# WKUP_CTRL_MMR0_CFG0 register map
Vendor: Texas Instruments
Registers are 32-bit, read-write, reset 0x0 unless marked. A register's access mark holds for its fields unless they carry their own. Offsets are as the file gives them; [hi:lo] are bit positions; {n}, {i} and the like mark numbered series.

## WKUP_CTRL_MMR0_CFG0 (part 5 of 11)
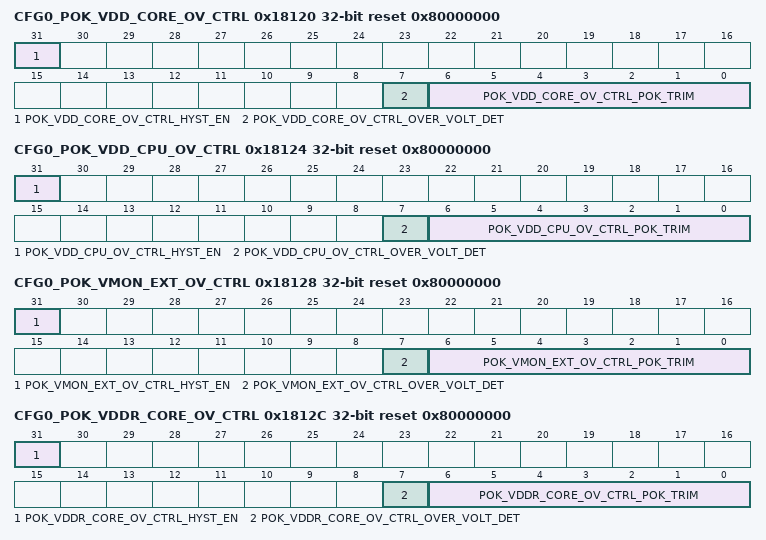
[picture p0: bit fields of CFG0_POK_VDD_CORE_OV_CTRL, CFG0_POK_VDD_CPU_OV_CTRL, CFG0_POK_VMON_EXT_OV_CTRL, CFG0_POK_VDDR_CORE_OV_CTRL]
0x18120 CFG0_POK_VDD_CORE_OV_CTRL reset 0x80000000
  [31] POK_VDD_CORE_OV_CTRL_HYST_EN — Enable POK hysteresis
  [7] POK_VDD_CORE_OV_CTRL_OVER_VOLT_DET — Over / under voltage detection mode 0 - Under voltage detection 1 - Over voltage detection
  [6:0] POK_VDD_CORE_OV_CTRL_POK_TRIM — POK trim bits. These bits are used to trim the comparator threshold voltage. See POK spec and efuse spec for details
0x18124 CFG0_POK_VDD_CPU_OV_CTRL reset 0x80000000
  [31] POK_VDD_CPU_OV_CTRL_HYST_EN — Enable POK hysteresis
  [7] POK_VDD_CPU_OV_CTRL_OVER_VOLT_DET — Over / under voltage detection mode 0 - Under voltage detection 1 - Over voltage detection
  [6:0] POK_VDD_CPU_OV_CTRL_POK_TRIM — POK trim bits. These bits are used to trim the comparator threshold voltage. See POK spec and efuse spec for details
0x18128 CFG0_POK_VMON_EXT_OV_CTRL reset 0x80000000
  [31] POK_VMON_EXT_OV_CTRL_HYST_EN — Enable POK hysteresis
  [7] POK_VMON_EXT_OV_CTRL_OVER_VOLT_DET — Over / under voltage detection mode 0 - Under voltage detection 1 - Over voltage detection
  [6:0] POK_VMON_EXT_OV_CTRL_POK_TRIM — POK trim bits. These bits are used to trim the comparator threshold voltage. See POK spec and efuse spec for details
0x1812C CFG0_POK_VDDR_CORE_OV_CTRL reset 0x80000000
  [31] POK_VDDR_CORE_OV_CTRL_HYST_EN — Enable POK hysteresis
  [7] POK_VDDR_CORE_OV_CTRL_OVER_VOLT_DET — Over / under voltage detection mode 0 - Under voltage detection 1 - Over voltage detection
  [6:0] POK_VDDR_CORE_OV_CTRL_POK_TRIM — POK trim bits. These bits are used to trim the comparator threshold voltage. See POK spec and efuse spec for details
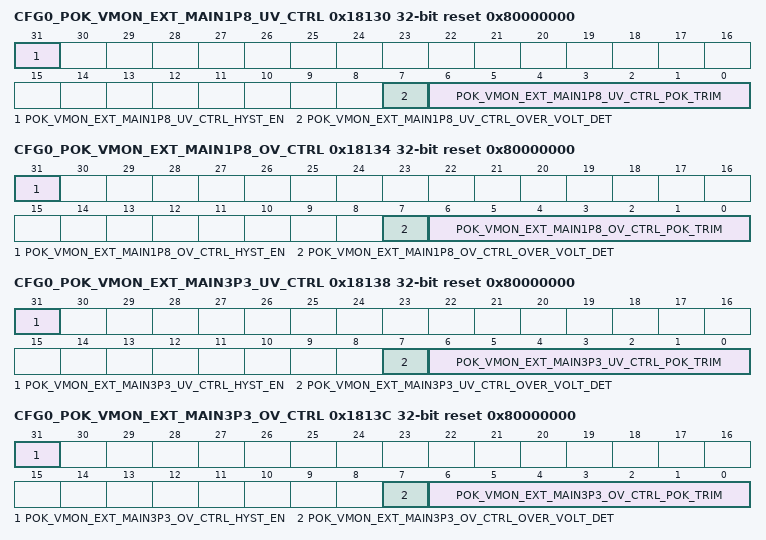
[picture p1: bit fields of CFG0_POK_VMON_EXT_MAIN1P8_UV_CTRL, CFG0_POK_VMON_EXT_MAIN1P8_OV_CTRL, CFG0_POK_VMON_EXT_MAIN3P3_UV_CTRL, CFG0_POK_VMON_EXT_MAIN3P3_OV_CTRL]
0x18130 CFG0_POK_VMON_EXT_MAIN1P8_UV_CTRL reset 0x80000000
  [31] POK_VMON_EXT_MAIN1P8_UV_CTRL_HYST_EN — Enable POK hysteresis
  [7] POK_VMON_EXT_MAIN1P8_UV_CTRL_OVER_VOLT_DET — Over / under voltage detection mode 0 - Under voltage detection 1 - Over voltage detection
  [6:0] POK_VMON_EXT_MAIN1P8_UV_CTRL_POK_TRIM — POK trim bits. These bits are used to trim the comparator threshold voltage. See POK spec and efuse spec for details
0x18134 CFG0_POK_VMON_EXT_MAIN1P8_OV_CTRL reset 0x80000000
  [31] POK_VMON_EXT_MAIN1P8_OV_CTRL_HYST_EN — Enable POK hysteresis
  [7] POK_VMON_EXT_MAIN1P8_OV_CTRL_OVER_VOLT_DET — Over / under voltage detection mode 0 - Under voltage detection 1 - Over voltage detection
  [6:0] POK_VMON_EXT_MAIN1P8_OV_CTRL_POK_TRIM — POK trim bits. These bits are used to trim the comparator threshold voltage. See POK spec and efuse spec for details
0x18138 CFG0_POK_VMON_EXT_MAIN3P3_UV_CTRL reset 0x80000000
  [31] POK_VMON_EXT_MAIN3P3_UV_CTRL_HYST_EN — Enable POK hysteresis
  [7] POK_VMON_EXT_MAIN3P3_UV_CTRL_OVER_VOLT_DET — Over / under voltage detection mode 0 - Under voltage detection 1 - Over voltage detection
  [6:0] POK_VMON_EXT_MAIN3P3_UV_CTRL_POK_TRIM — POK trim bits. These bits are used to trim the comparator threshold voltage. See POK spec and efuse spec for details
0x1813C CFG0_POK_VMON_EXT_MAIN3P3_OV_CTRL reset 0x80000000
  [31] POK_VMON_EXT_MAIN3P3_OV_CTRL_HYST_EN — Enable POK hysteresis
  [7] POK_VMON_EXT_MAIN3P3_OV_CTRL_OVER_VOLT_DET — Over / under voltage detection mode 0 - Under voltage detection 1 - Over voltage detection
  [6:0] POK_VMON_EXT_MAIN3P3_OV_CTRL_POK_TRIM — POK trim bits. These bits are used to trim the comparator threshold voltage. See POK spec and efuse spec for details
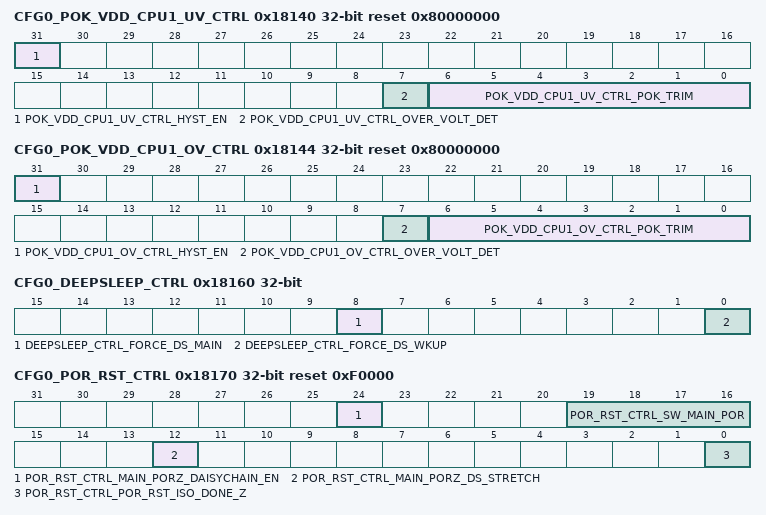
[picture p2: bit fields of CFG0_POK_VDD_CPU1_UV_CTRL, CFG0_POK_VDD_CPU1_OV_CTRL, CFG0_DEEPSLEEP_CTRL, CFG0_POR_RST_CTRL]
0x18140 CFG0_POK_VDD_CPU1_UV_CTRL reset 0x80000000
  [31] POK_VDD_CPU1_UV_CTRL_HYST_EN — Enable POK hysteresis
  [7] POK_VDD_CPU1_UV_CTRL_OVER_VOLT_DET — Over / under voltage detection mode 0 - Under voltage detection 1 - Over voltage detection
  [6:0] POK_VDD_CPU1_UV_CTRL_POK_TRIM — POK trim bits. These bits are used to trim the comparator threshold voltage. See POK spec and efuse spec for details
0x18144 CFG0_POK_VDD_CPU1_OV_CTRL reset 0x80000000
  [31] POK_VDD_CPU1_OV_CTRL_HYST_EN — Enable POK hysteresis
  [7] POK_VDD_CPU1_OV_CTRL_OVER_VOLT_DET — Over / under voltage detection mode 0 - Under voltage detection 1 - Over voltage detection
  [6:0] POK_VDD_CPU1_OV_CTRL_POK_TRIM — POK trim bits. These bits are used to trim the comparator threshold voltage. See POK spec and efuse spec for details
{0x18150+4i} CFG0_POK_RSV{i} access not given (i=0..3)
0x18160 CFG0_DEEPSLEEP_CTRL
  [8] DEEPSLEEP_CTRL_FORCE_DS_MAIN — Force all MAIN IOs into deepsleep mode when set
  [0] DEEPSLEEP_CTRL_FORCE_DS_WKUP — Force all WKUP IOs into deepsleep mode when set
0x18170 CFG0_POR_RST_CTRL reset 0xF0000
  [24] POR_RST_CTRL_MAIN_PORZ_DAISYCHAIN_EN — MAIN PORz daisy-chain event enable. Determines if MAIN PORz reset events affect daisy-chain wakeup 0 - DeepSleep MAIN PORz event is not part of daisy-chain 1 - DeepSleep MAIN PORz event is combined w/ other daisy chain events.
  [19:16] POR_RST_CTRL_SW_MAIN_POR — Main Domain software power-on reset. When set to 4'b0110, a power-on is issued to the MAIN voltage domain. (Bits will reset to 4'b1111 on reset of the Main Domain)
  [12] POR_RST_CTRL_MAIN_PORZ_DS_STRETCH — DeepSleep mode MAIN PORz stretch. 0 - No stretching 1 - Stretch the Main PORz event captured during DeepSleep mode
  [0] POR_RST_CTRL_POR_RST_ISO_DONE_Z — Reset isolation completion (active low). This bit should be cleared only after reset isolation of the MAIN domain is complete. 0 - POR reset propagates to MAIN domain 1 - POR reset blocked from MAIN domain
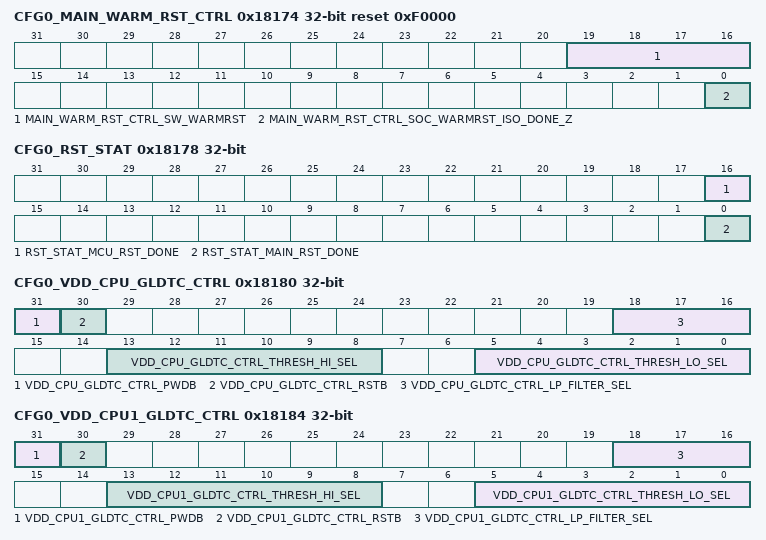
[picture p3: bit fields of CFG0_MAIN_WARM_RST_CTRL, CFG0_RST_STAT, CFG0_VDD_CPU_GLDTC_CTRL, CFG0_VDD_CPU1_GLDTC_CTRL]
0x18174 CFG0_MAIN_WARM_RST_CTRL reset 0xF0000
  [19:16] MAIN_WARM_RST_CTRL_SW_WARMRST — Main Domain software warm reset. When set to 4'b0110, a warm reset is issued to the MAIN voltage domain. (Bits will reset to 4'b1111 on reset of the Main Domain)
  [0] MAIN_WARM_RST_CTRL_SOC_WARMRST_ISO_DONE_Z — Reset isolation completion (active low). This bit should be cleared only after reset isolation of the MAIN domain is complete. 0 - Warm reset propagates to MAIN domain 1 - Warm reset blocked from MAIN domain
0x18178 CFG0_RST_STAT ro
  [16] RST_STAT_MCU_RST_DONE — Indicates MCU domain reset status. 0 - MCU domain is in reset 1 - MCU domain reset is complete
  [0] RST_STAT_MAIN_RST_DONE — Indicates MAIN domain Warm reset status. 0 - MAIN domain is in Warm reset 1 - MAIN domain Warm reset is complete
0x1817C CFG0_MCU_WARM_RST_CTRL reset 0xF0000
  [19:16] MCU_WARM_RST_CTRL_SW_WARMRST — Chip software warm reset. When set to 4'b0110, a warm reset is issued to the device (all voltage domains). (Bits will reset to 4'b1111 on reset completion.)
0x18180 CFG0_VDD_CPU_GLDTC_CTRL
  [31] VDD_CPU_GLDTC_CTRL_PWDB — Power down - active low. 0 - Disable all functions 1 - Enable glitch detectors
  [30] VDD_CPU_GLDTC_CTRL_RSTB — Reset - active low. To ensure proper operation, rstb must be not be de-asserted for at least 100 ns after power-up (pwdb de-asserted). Additionally, rstb must be toggled low at least 200 ns after any change in threshold or low-pass filter settings to prevent abnormal trigger events. 0 - Reset glitch detector flags 1 - Glitch detection flags are enabled
  [18:16] VDD_CPU_GLDTC_CTRL_LP_FILTER_SEL — Selects the glitch detect low-pass filter bandwidth Field values (others are reserved): 3'b000 - 150 kHz 3'b001 - 125 kHz 3'b010 - 100 kHz 3'b011 - 80 kHz 3'b100 - 60 kHz 3'b101 - 45 kHz 3'b110 - 30 kHz 3'b111 - 15 kHz
  [13:8] VDD_CPU_GLDTC_CTRL_THRESH_HI_SEL — Selects the high voltage glitch threshold as a percentage of the monitored voltage Field values (others are reserved): 6'b000000 - 93.5% of VDD 6'b000001 - 94.0% of VDD 6'b000010 - 94.5% of VDD 6'b000011 - 95.0% of VDD 6'b000100 - 95.5% of VDD 6'b000101 - 96.0% of VDD 6'b000110 - 96.5% of VDD 6'b000111 - 97.0% of VDD 6'b001000 - 97.5% of VDD 6'b001001 - 98.0% of VDD 6'b001010 - 98.5% of VDD 6'b001011 - 99.0% of VDD 6'b001100 - 99.5% of VDD 6'b001101 - 100.0% of VDD 6'b001110 - 100.5% of VDD 6'b001111 - 101.0% of VDD 6'b010000 - 101.5% of VDD 6'b010001 - 102.0% of VDD 6'b010010 - 102.5% of VDD 6'b010011 - 103.0% of VDD 6'b010100 - 103.5% of VDD 6'b010101 - 104.0% of VDD 6'b010110 - 104.5% of VDD 6'b010111 - 105.0% of VDD 6'b011000 - 105.5% of VDD 6'b011001 - 106.0% of VDD 6'b011010 - 106.5% of VDD 6'b011011 - 107.0% of VDD 6'b011100 - 107.5% of VDD 6'b011101 - 108.0% of VDD 6'b011110 - 108.5% of VDD 6'b011111 - 109.0% of VDD 6'b100000 - 109.5% of VDD 6'b100001 - 110.0% of VDD 6'b100010 - 111.0% of VDD 6'b100011 - 112.0% of VDD 6'b100100 - 113.0% of VDD 6'b100101 - 114.0% of VDD 6'b100110 - 115.0% of VDD 6'b100111 - 116.0% of VDD 6'b101000 - 117.0% of VDD 6'b101001 - 118.0% of VDD 6'b101010 - 119.0% of VDD 6'b101011 - 120.0% of VDD 6'b101100 - 121.0% of VDD 6'b101101 - 122.0% of VDD 6'b101110 - 123.0% of VDD 6'b101111 - 124.0% of VDD 6'b110000 - 125.0% of VDD 6'b110001 - 126.0% of VDD 6'b110010 - 127.0% of VDD 6'b110011 - 128.0% of VDD 6'b110100 - 129.0% of VDD 6'b110101 - 130.0% of VDD 6'b110110 - 131.0% of VDD 6'b110111 - 132.0% of VDD 6'b111000 - 133.0% of VDD 6'b111001 - 134.0% of VDD 6'b111010 - 135.0% of VDD 6'b111011 - 136.0% of VDD 6'b111100 - 137.0% of VDD 6'b111101 - 138.0% of VDD 6'b111110 - 139.0% of VDD 6'b111111 - 140.0% of VDD
  [5:0] VDD_CPU_GLDTC_CTRL_THRESH_LO_SEL — Selects the low voltage glitch threshold as a percentage of the monitored voltage Field values (others are reserved): 6'b000000 - 106.5% of VDD 6'b000001 - 106.0% of VDD 6'b000010 - 105.5% of VDD 6'b000011 - 105.0% of VDD 6'b000100 - 104.5% of VDD 6'b000101 - 104.0% of VDD 6'b000110 - 103.5% of VDD 6'b000111 - 103.0% of VDD 6'b001000 - 102.5% of VDD 6'b001001 - 102.0% of VDD 6'b001010 - 101.5% of VDD 6'b001011 - 101.0% of VDD 6'b001100 - 100.5% of VDD 6'b001101 - 100.0% of VDD 6'b001110 - 99.5% of VDD 6'b001111 - 99.0% of VDD 6'b010000 - 98.5% of VDD 6'b010001 - 98.0% of VDD 6'b010010 - 97.5% of VDD 6'b010011 - 97.0% of VDD 6'b010100 - 96.5% of VDD 6'b010101 - 96.0% of VDD 6'b010110 - 95.5% of VDD 6'b010111 - 95.0% of VDD 6'b011000 - 94.5% of VDD 6'b011001 - 94.0% of VDD 6'b011010 - 93.5% of VDD 6'b011011 - 93.0% of VDD 6'b011100 - 92.5% of VDD 6'b011101 - 92.0% of VDD 6'b011110 - 91.5% of VDD 6'b011111 - 91.0% of VDD 6'b100000 - 90.5% of VDD 6'b100001 - 90.0% of VDD 6'b100010 - 89.0% of VDD 6'b100011 - 88.0% of VDD 6'b100100 - 87.0% of VDD 6'b100101 - 86.0% of VDD 6'b100110 - 85.0% of VDD 6'b100111 - 84.0% of VDD 6'b101000 - 83.0% of VDD 6'b101001 - 82.0% of VDD 6'b101010 - 81.0% of VDD 6'b101011 - 80.0% of VDD 6'b101100 - 79.0% of VDD 6'b101101 - 78.0% of VDD 6'b101110 - 77.0% of VDD 6'b101111 - 76.0% of VDD 6'b110000 - 75.0% of VDD 6'b110001 - 74.0% of VDD 6'b110010 - 73.0% of VDD 6'b110011 - 72.0% of VDD 6'b110100 - 71.0% of VDD 6'b110101 - 70.0% of VDD 6'b110110 - 69.0% of VDD 6'b110111 - 68.0% of VDD 6'b111000 - 67.0% of VDD 6'b111001 - 66.0% of VDD 6'b111010 - 65.0% of VDD 6'b111011 - 64.0% of VDD 6'b111100 - 63.0% of VDD 6'b111101 - 62.0% of VDD 6'b111110 - 61.0% of VDD 6'b111111 - 60.0% of VDD
0x18184 CFG0_VDD_CPU1_GLDTC_CTRL
  [31] VDD_CPU1_GLDTC_CTRL_PWDB — Power down - active low. 0 - Disable all functions 1 - Enable glitch detectors
  [30] VDD_CPU1_GLDTC_CTRL_RSTB — Reset - active low. To ensure proper operation, rstb must be not be de-asserted for at least 100 ns after power-up (pwdb de-asserted). Additionally, rstb must be toggled low at least 200 ns after any change in threshold or low-pass filter settings to prevent abnormal trigger events. 0 - Reset glitch detector flags 1 - Glitch detection flags are enabled
  [18:16] VDD_CPU1_GLDTC_CTRL_LP_FILTER_SEL — Selects the glitch detect low-pass filter bandwidth Field values (others are reserved): 3'b000 - 150 kHz 3'b001 - 125 kHz 3'b010 - 100 kHz 3'b011 - 80 kHz 3'b100 - 60 kHz 3'b101 - 45 kHz 3'b110 - 30 kHz 3'b111 - 15 kHz
  [13:8] VDD_CPU1_GLDTC_CTRL_THRESH_HI_SEL — Selects the high voltage glitch threshold as a percentage of the monitored voltage Field values (others are reserved): 6'b000000 - 93.5% of VDD 6'b000001 - 94.0% of VDD 6'b000010 - 94.5% of VDD 6'b000011 - 95.0% of VDD 6'b000100 - 95.5% of VDD 6'b000101 - 96.0% of VDD 6'b000110 - 96.5% of VDD 6'b000111 - 97.0% of VDD 6'b001000 - 97.5% of VDD 6'b001001 - 98.0% of VDD 6'b001010 - 98.5% of VDD 6'b001011 - 99.0% of VDD 6'b001100 - 99.5% of VDD 6'b001101 - 100.0% of VDD 6'b001110 - 100.5% of VDD 6'b001111 - 101.0% of VDD 6'b010000 - 101.5% of VDD 6'b010001 - 102.0% of VDD 6'b010010 - 102.5% of VDD 6'b010011 - 103.0% of VDD 6'b010100 - 103.5% of VDD 6'b010101 - 104.0% of VDD 6'b010110 - 104.5% of VDD 6'b010111 - 105.0% of VDD 6'b011000 - 105.5% of VDD 6'b011001 - 106.0% of VDD 6'b011010 - 106.5% of VDD 6'b011011 - 107.0% of VDD 6'b011100 - 107.5% of VDD 6'b011101 - 108.0% of VDD 6'b011110 - 108.5% of VDD 6'b011111 - 109.0% of VDD 6'b100000 - 109.5% of VDD 6'b100001 - 110.0% of VDD 6'b100010 - 111.0% of VDD 6'b100011 - 112.0% of VDD 6'b100100 - 113.0% of VDD 6'b100101 - 114.0% of VDD 6'b100110 - 115.0% of VDD 6'b100111 - 116.0% of VDD 6'b101000 - 117.0% of VDD 6'b101001 - 118.0% of VDD 6'b101010 - 119.0% of VDD 6'b101011 - 120.0% of VDD 6'b101100 - 121.0% of VDD 6'b101101 - 122.0% of VDD 6'b101110 - 123.0% of VDD 6'b101111 - 124.0% of VDD 6'b110000 - 125.0% of VDD 6'b110001 - 126.0% of VDD 6'b110010 - 127.0% of VDD 6'b110011 - 128.0% of VDD 6'b110100 - 129.0% of VDD 6'b110101 - 130.0% of VDD 6'b110110 - 131.0% of VDD 6'b110111 - 132.0% of VDD 6'b111000 - 133.0% of VDD 6'b111001 - 134.0% of VDD 6'b111010 - 135.0% of VDD 6'b111011 - 136.0% of VDD 6'b111100 - 137.0% of VDD 6'b111101 - 138.0% of VDD 6'b111110 - 139.0% of VDD 6'b111111 - 140.0% of VDD
  [5:0] VDD_CPU1_GLDTC_CTRL_THRESH_LO_SEL — Selects the low voltage glitch threshold as a percentage of the monitored voltage Field values (others are reserved): 6'b000000 - 106.5% of VDD 6'b000001 - 106.0% of VDD 6'b000010 - 105.5% of VDD 6'b000011 - 105.0% of VDD 6'b000100 - 104.5% of VDD 6'b000101 - 104.0% of VDD 6'b000110 - 103.5% of VDD 6'b000111 - 103.0% of VDD 6'b001000 - 102.5% of VDD 6'b001001 - 102.0% of VDD 6'b001010 - 101.5% of VDD 6'b001011 - 101.0% of VDD 6'b001100 - 100.5% of VDD 6'b001101 - 100.0% of VDD 6'b001110 - 99.5% of VDD 6'b001111 - 99.0% of VDD 6'b010000 - 98.5% of VDD 6'b010001 - 98.0% of VDD 6'b010010 - 97.5% of VDD 6'b010011 - 97.0% of VDD 6'b010100 - 96.5% of VDD 6'b010101 - 96.0% of VDD 6'b010110 - 95.5% of VDD 6'b010111 - 95.0% of VDD 6'b011000 - 94.5% of VDD 6'b011001 - 94.0% of VDD 6'b011010 - 93.5% of VDD 6'b011011 - 93.0% of VDD 6'b011100 - 92.5% of VDD 6'b011101 - 92.0% of VDD 6'b011110 - 91.5% of VDD 6'b011111 - 91.0% of VDD 6'b100000 - 90.5% of VDD 6'b100001 - 90.0% of VDD 6'b100010 - 89.0% of VDD 6'b100011 - 88.0% of VDD 6'b100100 - 87.0% of VDD 6'b100101 - 86.0% of VDD 6'b100110 - 85.0% of VDD 6'b100111 - 84.0% of VDD 6'b101000 - 83.0% of VDD 6'b101001 - 82.0% of VDD 6'b101010 - 81.0% of VDD 6'b101011 - 80.0% of VDD 6'b101100 - 79.0% of VDD 6'b101101 - 78.0% of VDD 6'b101110 - 77.0% of VDD 6'b101111 - 76.0% of VDD 6'b110000 - 75.0% of VDD 6'b110001 - 74.0% of VDD 6'b110010 - 73.0% of VDD 6'b110011 - 72.0% of VDD 6'b110100 - 71.0% of VDD 6'b110101 - 70.0% of VDD 6'b110110 - 69.0% of VDD 6'b110111 - 68.0% of VDD 6'b111000 - 67.0% of VDD 6'b111001 - 66.0% of VDD 6'b111010 - 65.0% of VDD 6'b111011 - 64.0% of VDD 6'b111100 - 63.0% of VDD 6'b111101 - 62.0% of VDD 6'b111110 - 61.0% of VDD 6'b111111 - 60.0% of VDD
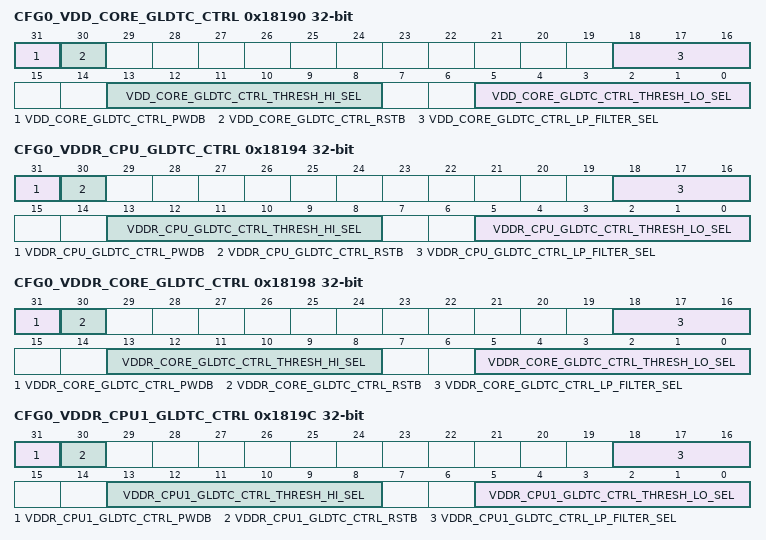
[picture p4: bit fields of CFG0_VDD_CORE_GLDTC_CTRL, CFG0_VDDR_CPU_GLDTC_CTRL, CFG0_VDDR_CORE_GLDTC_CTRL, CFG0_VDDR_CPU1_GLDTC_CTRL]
0x18190 CFG0_VDD_CORE_GLDTC_CTRL
  [31] VDD_CORE_GLDTC_CTRL_PWDB — Power down - active low. 0 - Disable all functions 1 - Enable glitch detectors
  [30] VDD_CORE_GLDTC_CTRL_RSTB — Reset - active low. To ensure proper operation, rstb must be not be de-asserted for at least 100 ns after power-up (pwdb de-asserted). Additionally, rstb must be toggled low at least 200 ns after any change in threshold or low-pass filter settings to prevent abnormal trigger events. 0 - Reset glitch detector flags 1 - Glitch detection flags are enabled
  [18:16] VDD_CORE_GLDTC_CTRL_LP_FILTER_SEL — Selects the glitch detect low-pass filter bandwidth Field values (others are reserved): 3'b000 - 150 kHz 3'b001 - 125 kHz 3'b010 - 100 kHz 3'b011 - 80 kHz 3'b100 - 60 kHz 3'b101 - 45 kHz 3'b110 - 30 kHz 3'b111 - 15 kHz
  [13:8] VDD_CORE_GLDTC_CTRL_THRESH_HI_SEL — Selects the high voltage glitch threshold as a percentage of the monitored voltage Field values (others are reserved): 6'b000000 - 93.5% of VDD 6'b000001 - 94.0% of VDD 6'b000010 - 94.5% of VDD 6'b000011 - 95.0% of VDD 6'b000100 - 95.5% of VDD 6'b000101 - 96.0% of VDD 6'b000110 - 96.5% of VDD 6'b000111 - 97.0% of VDD 6'b001000 - 97.5% of VDD 6'b001001 - 98.0% of VDD 6'b001010 - 98.5% of VDD 6'b001011 - 99.0% of VDD 6'b001100 - 99.5% of VDD 6'b001101 - 100.0% of VDD 6'b001110 - 100.5% of VDD 6'b001111 - 101.0% of VDD 6'b010000 - 101.5% of VDD 6'b010001 - 102.0% of VDD 6'b010010 - 102.5% of VDD 6'b010011 - 103.0% of VDD 6'b010100 - 103.5% of VDD 6'b010101 - 104.0% of VDD 6'b010110 - 104.5% of VDD 6'b010111 - 105.0% of VDD 6'b011000 - 105.5% of VDD 6'b011001 - 106.0% of VDD 6'b011010 - 106.5% of VDD 6'b011011 - 107.0% of VDD 6'b011100 - 107.5% of VDD 6'b011101 - 108.0% of VDD 6'b011110 - 108.5% of VDD 6'b011111 - 109.0% of VDD 6'b100000 - 109.5% of VDD 6'b100001 - 110.0% of VDD 6'b100010 - 111.0% of VDD 6'b100011 - 112.0% of VDD 6'b100100 - 113.0% of VDD 6'b100101 - 114.0% of VDD 6'b100110 - 115.0% of VDD 6'b100111 - 116.0% of VDD 6'b101000 - 117.0% of VDD 6'b101001 - 118.0% of VDD 6'b101010 - 119.0% of VDD 6'b101011 - 120.0% of VDD 6'b101100 - 121.0% of VDD 6'b101101 - 122.0% of VDD 6'b101110 - 123.0% of VDD 6'b101111 - 124.0% of VDD 6'b110000 - 125.0% of VDD 6'b110001 - 126.0% of VDD 6'b110010 - 127.0% of VDD 6'b110011 - 128.0% of VDD 6'b110100 - 129.0% of VDD 6'b110101 - 130.0% of VDD 6'b110110 - 131.0% of VDD 6'b110111 - 132.0% of VDD 6'b111000 - 133.0% of VDD 6'b111001 - 134.0% of VDD 6'b111010 - 135.0% of VDD 6'b111011 - 136.0% of VDD 6'b111100 - 137.0% of VDD 6'b111101 - 138.0% of VDD 6'b111110 - 139.0% of VDD 6'b111111 - 140.0% of VDD
  [5:0] VDD_CORE_GLDTC_CTRL_THRESH_LO_SEL — Selects the low voltage glitch threshold as a percentage of the monitored voltage Field values (others are reserved): 6'b000000 - 106.5% of VDD 6'b000001 - 106.0% of VDD 6'b000010 - 105.5% of VDD 6'b000011 - 105.0% of VDD 6'b000100 - 104.5% of VDD 6'b000101 - 104.0% of VDD 6'b000110 - 103.5% of VDD 6'b000111 - 103.0% of VDD 6'b001000 - 102.5% of VDD 6'b001001 - 102.0% of VDD 6'b001010 - 101.5% of VDD 6'b001011 - 101.0% of VDD 6'b001100 - 100.5% of VDD 6'b001101 - 100.0% of VDD 6'b001110 - 99.5% of VDD 6'b001111 - 99.0% of VDD 6'b010000 - 98.5% of VDD 6'b010001 - 98.0% of VDD 6'b010010 - 97.5% of VDD 6'b010011 - 97.0% of VDD 6'b010100 - 96.5% of VDD 6'b010101 - 96.0% of VDD 6'b010110 - 95.5% of VDD 6'b010111 - 95.0% of VDD 6'b011000 - 94.5% of VDD 6'b011001 - 94.0% of VDD 6'b011010 - 93.5% of VDD 6'b011011 - 93.0% of VDD 6'b011100 - 92.5% of VDD 6'b011101 - 92.0% of VDD 6'b011110 - 91.5% of VDD 6'b011111 - 91.0% of VDD 6'b100000 - 90.5% of VDD 6'b100001 - 90.0% of VDD 6'b100010 - 89.0% of VDD 6'b100011 - 88.0% of VDD 6'b100100 - 87.0% of VDD 6'b100101 - 86.0% of VDD 6'b100110 - 85.0% of VDD 6'b100111 - 84.0% of VDD 6'b101000 - 83.0% of VDD 6'b101001 - 82.0% of VDD 6'b101010 - 81.0% of VDD 6'b101011 - 80.0% of VDD 6'b101100 - 79.0% of VDD 6'b101101 - 78.0% of VDD 6'b101110 - 77.0% of VDD 6'b101111 - 76.0% of VDD 6'b110000 - 75.0% of VDD 6'b110001 - 74.0% of VDD 6'b110010 - 73.0% of VDD 6'b110011 - 72.0% of VDD 6'b110100 - 71.0% of VDD 6'b110101 - 70.0% of VDD 6'b110110 - 69.0% of VDD 6'b110111 - 68.0% of VDD 6'b111000 - 67.0% of VDD 6'b111001 - 66.0% of VDD 6'b111010 - 65.0% of VDD 6'b111011 - 64.0% of VDD 6'b111100 - 63.0% of VDD 6'b111101 - 62.0% of VDD 6'b111110 - 61.0% of VDD 6'b111111 - 60.0% of VDD
0x18194 CFG0_VDDR_CPU_GLDTC_CTRL
  [31] VDDR_CPU_GLDTC_CTRL_PWDB — Power down - active low. 0 - Disable all functions 1 - Enable glitch detectors
  [30] VDDR_CPU_GLDTC_CTRL_RSTB — Reset - active low. To ensure proper operation, rstb must be not be de-asserted for at least 100 ns after power-up (pwdb de-asserted). Additionally, rstb must be toggled low at least 200 ns after any change in threshold or low-pass filter settings to prevent abnormal trigger events. 0 - Reset glitch detector flags 1 - Glitch detection flags are enabled
  [18:16] VDDR_CPU_GLDTC_CTRL_LP_FILTER_SEL — Selects the glitch detect low-pass filter bandwidth Field values (others are reserved): 3'b000 - 150 kHz 3'b001 - 125 kHz 3'b010 - 100 kHz 3'b011 - 80 kHz 3'b100 - 60 kHz 3'b101 - 45 kHz 3'b110 - 30 kHz 3'b111 - 15 kHz
  [13:8] VDDR_CPU_GLDTC_CTRL_THRESH_HI_SEL — Selects the high voltage glitch threshold as a percentage of the monitored voltage Field values (others are reserved): 6'b000000 - 93.5% of VDD 6'b000001 - 94.0% of VDD 6'b000010 - 94.5% of VDD 6'b000011 - 95.0% of VDD 6'b000100 - 95.5% of VDD 6'b000101 - 96.0% of VDD 6'b000110 - 96.5% of VDD 6'b000111 - 97.0% of VDD 6'b001000 - 97.5% of VDD 6'b001001 - 98.0% of VDD 6'b001010 - 98.5% of VDD 6'b001011 - 99.0% of VDD 6'b001100 - 99.5% of VDD 6'b001101 - 100.0% of VDD 6'b001110 - 100.5% of VDD 6'b001111 - 101.0% of VDD 6'b010000 - 101.5% of VDD 6'b010001 - 102.0% of VDD 6'b010010 - 102.5% of VDD 6'b010011 - 103.0% of VDD 6'b010100 - 103.5% of VDD 6'b010101 - 104.0% of VDD 6'b010110 - 104.5% of VDD 6'b010111 - 105.0% of VDD 6'b011000 - 105.5% of VDD 6'b011001 - 106.0% of VDD 6'b011010 - 106.5% of VDD 6'b011011 - 107.0% of VDD 6'b011100 - 107.5% of VDD 6'b011101 - 108.0% of VDD 6'b011110 - 108.5% of VDD 6'b011111 - 109.0% of VDD 6'b100000 - 109.5% of VDD 6'b100001 - 110.0% of VDD 6'b100010 - 111.0% of VDD 6'b100011 - 112.0% of VDD 6'b100100 - 113.0% of VDD 6'b100101 - 114.0% of VDD 6'b100110 - 115.0% of VDD 6'b100111 - 116.0% of VDD 6'b101000 - 117.0% of VDD 6'b101001 - 118.0% of VDD 6'b101010 - 119.0% of VDD 6'b101011 - 120.0% of VDD 6'b101100 - 121.0% of VDD 6'b101101 - 122.0% of VDD 6'b101110 - 123.0% of VDD 6'b101111 - 124.0% of VDD 6'b110000 - 125.0% of VDD 6'b110001 - 126.0% of VDD 6'b110010 - 127.0% of VDD 6'b110011 - 128.0% of VDD 6'b110100 - 129.0% of VDD 6'b110101 - 130.0% of VDD 6'b110110 - 131.0% of VDD 6'b110111 - 132.0% of VDD 6'b111000 - 133.0% of VDD 6'b111001 - 134.0% of VDD 6'b111010 - 135.0% of VDD 6'b111011 - 136.0% of VDD 6'b111100 - 137.0% of VDD 6'b111101 - 138.0% of VDD 6'b111110 - 139.0% of VDD 6'b111111 - 140.0% of VDD
  [5:0] VDDR_CPU_GLDTC_CTRL_THRESH_LO_SEL — Selects the low voltage glitch threshold as a percentage of the monitored voltage Field values (others are reserved): 6'b000000 - 106.5% of VDD 6'b000001 - 106.0% of VDD 6'b000010 - 105.5% of VDD 6'b000011 - 105.0% of VDD 6'b000100 - 104.5% of VDD 6'b000101 - 104.0% of VDD 6'b000110 - 103.5% of VDD 6'b000111 - 103.0% of VDD 6'b001000 - 102.5% of VDD 6'b001001 - 102.0% of VDD 6'b001010 - 101.5% of VDD 6'b001011 - 101.0% of VDD 6'b001100 - 100.5% of VDD 6'b001101 - 100.0% of VDD 6'b001110 - 99.5% of VDD 6'b001111 - 99.0% of VDD 6'b010000 - 98.5% of VDD 6'b010001 - 98.0% of VDD 6'b010010 - 97.5% of VDD 6'b010011 - 97.0% of VDD 6'b010100 - 96.5% of VDD 6'b010101 - 96.0% of VDD 6'b010110 - 95.5% of VDD 6'b010111 - 95.0% of VDD 6'b011000 - 94.5% of VDD 6'b011001 - 94.0% of VDD 6'b011010 - 93.5% of VDD 6'b011011 - 93.0% of VDD 6'b011100 - 92.5% of VDD 6'b011101 - 92.0% of VDD 6'b011110 - 91.5% of VDD 6'b011111 - 91.0% of VDD 6'b100000 - 90.5% of VDD 6'b100001 - 90.0% of VDD 6'b100010 - 89.0% of VDD 6'b100011 - 88.0% of VDD 6'b100100 - 87.0% of VDD 6'b100101 - 86.0% of VDD 6'b100110 - 85.0% of VDD 6'b100111 - 84.0% of VDD 6'b101000 - 83.0% of VDD 6'b101001 - 82.0% of VDD 6'b101010 - 81.0% of VDD 6'b101011 - 80.0% of VDD 6'b101100 - 79.0% of VDD 6'b101101 - 78.0% of VDD 6'b101110 - 77.0% of VDD 6'b101111 - 76.0% of VDD 6'b110000 - 75.0% of VDD 6'b110001 - 74.0% of VDD 6'b110010 - 73.0% of VDD 6'b110011 - 72.0% of VDD 6'b110100 - 71.0% of VDD 6'b110101 - 70.0% of VDD 6'b110110 - 69.0% of VDD 6'b110111 - 68.0% of VDD 6'b111000 - 67.0% of VDD 6'b111001 - 66.0% of VDD 6'b111010 - 65.0% of VDD 6'b111011 - 64.0% of VDD 6'b111100 - 63.0% of VDD 6'b111101 - 62.0% of VDD 6'b111110 - 61.0% of VDD 6'b111111 - 60.0% of VDD
0x18198 CFG0_VDDR_CORE_GLDTC_CTRL
  [31] VDDR_CORE_GLDTC_CTRL_PWDB — Power down - active low. 0 - Disable all functions 1 - Enable glitch detectors
  [30] VDDR_CORE_GLDTC_CTRL_RSTB — Reset - active low. To ensure proper operation, rstb must be not be de-asserted for at least 100 ns after power-up (pwdb de-asserted). Additionally, rstb must be toggled low at least 200 ns after any change in threshold or low-pass filter settings to prevent abnormal trigger events. 0 - Reset glitch detector flags 1 - Glitch detection flags are enabled
  [18:16] VDDR_CORE_GLDTC_CTRL_LP_FILTER_SEL — Selects the glitch detect low-pass filter bandwidth Field values (others are reserved): 3'b000 - 150 kHz 3'b001 - 125 kHz 3'b010 - 100 kHz 3'b011 - 80 kHz 3'b100 - 60 kHz 3'b101 - 45 kHz 3'b110 - 30 kHz 3'b111 - 15 kHz
  [13:8] VDDR_CORE_GLDTC_CTRL_THRESH_HI_SEL — Selects the high voltage glitch threshold as a percentage of the monitored voltage Field values (others are reserved): 6'b000000 - 93.5% of VDD 6'b000001 - 94.0% of VDD 6'b000010 - 94.5% of VDD 6'b000011 - 95.0% of VDD 6'b000100 - 95.5% of VDD 6'b000101 - 96.0% of VDD 6'b000110 - 96.5% of VDD 6'b000111 - 97.0% of VDD 6'b001000 - 97.5% of VDD 6'b001001 - 98.0% of VDD 6'b001010 - 98.5% of VDD 6'b001011 - 99.0% of VDD 6'b001100 - 99.5% of VDD 6'b001101 - 100.0% of VDD 6'b001110 - 100.5% of VDD 6'b001111 - 101.0% of VDD 6'b010000 - 101.5% of VDD 6'b010001 - 102.0% of VDD 6'b010010 - 102.5% of VDD 6'b010011 - 103.0% of VDD 6'b010100 - 103.5% of VDD 6'b010101 - 104.0% of VDD 6'b010110 - 104.5% of VDD 6'b010111 - 105.0% of VDD 6'b011000 - 105.5% of VDD 6'b011001 - 106.0% of VDD 6'b011010 - 106.5% of VDD 6'b011011 - 107.0% of VDD 6'b011100 - 107.5% of VDD 6'b011101 - 108.0% of VDD 6'b011110 - 108.5% of VDD 6'b011111 - 109.0% of VDD 6'b100000 - 109.5% of VDD 6'b100001 - 110.0% of VDD 6'b100010 - 111.0% of VDD 6'b100011 - 112.0% of VDD 6'b100100 - 113.0% of VDD 6'b100101 - 114.0% of VDD 6'b100110 - 115.0% of VDD 6'b100111 - 116.0% of VDD 6'b101000 - 117.0% of VDD 6'b101001 - 118.0% of VDD 6'b101010 - 119.0% of VDD 6'b101011 - 120.0% of VDD 6'b101100 - 121.0% of VDD 6'b101101 - 122.0% of VDD 6'b101110 - 123.0% of VDD 6'b101111 - 124.0% of VDD 6'b110000 - 125.0% of VDD 6'b110001 - 126.0% of VDD 6'b110010 - 127.0% of VDD 6'b110011 - 128.0% of VDD 6'b110100 - 129.0% of VDD 6'b110101 - 130.0% of VDD 6'b110110 - 131.0% of VDD 6'b110111 - 132.0% of VDD 6'b111000 - 133.0% of VDD 6'b111001 - 134.0% of VDD 6'b111010 - 135.0% of VDD 6'b111011 - 136.0% of VDD 6'b111100 - 137.0% of VDD 6'b111101 - 138.0% of VDD 6'b111110 - 139.0% of VDD 6'b111111 - 140.0% of VDD
  [5:0] VDDR_CORE_GLDTC_CTRL_THRESH_LO_SEL — Selects the low voltage glitch threshold as a percentage of the monitored voltage Field values (others are reserved): 6'b000000 - 106.5% of VDD 6'b000001 - 106.0% of VDD 6'b000010 - 105.5% of VDD 6'b000011 - 105.0% of VDD 6'b000100 - 104.5% of VDD 6'b000101 - 104.0% of VDD 6'b000110 - 103.5% of VDD 6'b000111 - 103.0% of VDD 6'b001000 - 102.5% of VDD 6'b001001 - 102.0% of VDD 6'b001010 - 101.5% of VDD 6'b001011 - 101.0% of VDD 6'b001100 - 100.5% of VDD 6'b001101 - 100.0% of VDD 6'b001110 - 99.5% of VDD 6'b001111 - 99.0% of VDD 6'b010000 - 98.5% of VDD 6'b010001 - 98.0% of VDD 6'b010010 - 97.5% of VDD 6'b010011 - 97.0% of VDD 6'b010100 - 96.5% of VDD 6'b010101 - 96.0% of VDD 6'b010110 - 95.5% of VDD 6'b010111 - 95.0% of VDD 6'b011000 - 94.5% of VDD 6'b011001 - 94.0% of VDD 6'b011010 - 93.5% of VDD 6'b011011 - 93.0% of VDD 6'b011100 - 92.5% of VDD 6'b011101 - 92.0% of VDD 6'b011110 - 91.5% of VDD 6'b011111 - 91.0% of VDD 6'b100000 - 90.5% of VDD 6'b100001 - 90.0% of VDD 6'b100010 - 89.0% of VDD 6'b100011 - 88.0% of VDD 6'b100100 - 87.0% of VDD 6'b100101 - 86.0% of VDD 6'b100110 - 85.0% of VDD 6'b100111 - 84.0% of VDD 6'b101000 - 83.0% of VDD 6'b101001 - 82.0% of VDD 6'b101010 - 81.0% of VDD 6'b101011 - 80.0% of VDD 6'b101100 - 79.0% of VDD 6'b101101 - 78.0% of VDD 6'b101110 - 77.0% of VDD 6'b101111 - 76.0% of VDD 6'b110000 - 75.0% of VDD 6'b110001 - 74.0% of VDD 6'b110010 - 73.0% of VDD 6'b110011 - 72.0% of VDD 6'b110100 - 71.0% of VDD 6'b110101 - 70.0% of VDD 6'b110110 - 69.0% of VDD 6'b110111 - 68.0% of VDD 6'b111000 - 67.0% of VDD 6'b111001 - 66.0% of VDD 6'b111010 - 65.0% of VDD 6'b111011 - 64.0% of VDD 6'b111100 - 63.0% of VDD 6'b111101 - 62.0% of VDD 6'b111110 - 61.0% of VDD 6'b111111 - 60.0% of VDD
0x1819C CFG0_VDDR_CPU1_GLDTC_CTRL
  [31] VDDR_CPU1_GLDTC_CTRL_PWDB — Power down - active low. 0 - Disable all functions 1 - Enable glitch detectors
  [30] VDDR_CPU1_GLDTC_CTRL_RSTB — Reset - active low. To ensure proper operation, rstb must be not be de-asserted for at least 100 ns after power-up (pwdb de-asserted). Additionally, rstb must be toggled low at least 200 ns after any change in threshold or low-pass filter settings to prevent abnormal trigger events. 0 - Reset glitch detector flags 1 - Glitch detection flags are enabled
  [18:16] VDDR_CPU1_GLDTC_CTRL_LP_FILTER_SEL — Selects the glitch detect low-pass filter bandwidth Field values (others are reserved): 3'b000 - 150 kHz 3'b001 - 125 kHz 3'b010 - 100 kHz 3'b011 - 80 kHz 3'b100 - 60 kHz 3'b101 - 45 kHz 3'b110 - 30 kHz 3'b111 - 15 kHz
  [13:8] VDDR_CPU1_GLDTC_CTRL_THRESH_HI_SEL — Selects the high voltage glitch threshold as a percentage of the monitored voltage Field values (others are reserved): 6'b000000 - 93.5% of VDD 6'b000001 - 94.0% of VDD 6'b000010 - 94.5% of VDD 6'b000011 - 95.0% of VDD 6'b000100 - 95.5% of VDD 6'b000101 - 96.0% of VDD 6'b000110 - 96.5% of VDD 6'b000111 - 97.0% of VDD 6'b001000 - 97.5% of VDD 6'b001001 - 98.0% of VDD 6'b001010 - 98.5% of VDD 6'b001011 - 99.0% of VDD 6'b001100 - 99.5% of VDD 6'b001101 - 100.0% of VDD 6'b001110 - 100.5% of VDD 6'b001111 - 101.0% of VDD 6'b010000 - 101.5% of VDD 6'b010001 - 102.0% of VDD 6'b010010 - 102.5% of VDD 6'b010011 - 103.0% of VDD 6'b010100 - 103.5% of VDD 6'b010101 - 104.0% of VDD 6'b010110 - 104.5% of VDD 6'b010111 - 105.0% of VDD 6'b011000 - 105.5% of VDD 6'b011001 - 106.0% of VDD 6'b011010 - 106.5% of VDD 6'b011011 - 107.0% of VDD 6'b011100 - 107.5% of VDD 6'b011101 - 108.0% of VDD 6'b011110 - 108.5% of VDD 6'b011111 - 109.0% of VDD 6'b100000 - 109.5% of VDD 6'b100001 - 110.0% of VDD 6'b100010 - 111.0% of VDD 6'b100011 - 112.0% of VDD 6'b100100 - 113.0% of VDD 6'b100101 - 114.0% of VDD 6'b100110 - 115.0% of VDD 6'b100111 - 116.0% of VDD 6'b101000 - 117.0% of VDD 6'b101001 - 118.0% of VDD 6'b101010 - 119.0% of VDD 6'b101011 - 120.0% of VDD 6'b101100 - 121.0% of VDD 6'b101101 - 122.0% of VDD 6'b101110 - 123.0% of VDD 6'b101111 - 124.0% of VDD 6'b110000 - 125.0% of VDD 6'b110001 - 126.0% of VDD 6'b110010 - 127.0% of VDD 6'b110011 - 128.0% of VDD 6'b110100 - 129.0% of VDD 6'b110101 - 130.0% of VDD 6'b110110 - 131.0% of VDD 6'b110111 - 132.0% of VDD 6'b111000 - 133.0% of VDD 6'b111001 - 134.0% of VDD 6'b111010 - 135.0% of VDD 6'b111011 - 136.0% of VDD 6'b111100 - 137.0% of VDD 6'b111101 - 138.0% of VDD 6'b111110 - 139.0% of VDD 6'b111111 - 140.0% of VDD
  [5:0] VDDR_CPU1_GLDTC_CTRL_THRESH_LO_SEL — Selects the low voltage glitch threshold as a percentage of the monitored voltage Field values (others are reserved): 6'b000000 - 106.5% of VDD 6'b000001 - 106.0% of VDD 6'b000010 - 105.5% of VDD 6'b000011 - 105.0% of VDD 6'b000100 - 104.5% of VDD 6'b000101 - 104.0% of VDD 6'b000110 - 103.5% of VDD 6'b000111 - 103.0% of VDD 6'b001000 - 102.5% of VDD 6'b001001 - 102.0% of VDD 6'b001010 - 101.5% of VDD 6'b001011 - 101.0% of VDD 6'b001100 - 100.5% of VDD 6'b001101 - 100.0% of VDD 6'b001110 - 99.5% of VDD 6'b001111 - 99.0% of VDD 6'b010000 - 98.5% of VDD 6'b010001 - 98.0% of VDD 6'b010010 - 97.5% of VDD 6'b010011 - 97.0% of VDD 6'b010100 - 96.5% of VDD 6'b010101 - 96.0% of VDD 6'b010110 - 95.5% of VDD 6'b010111 - 95.0% of VDD 6'b011000 - 94.5% of VDD 6'b011001 - 94.0% of VDD 6'b011010 - 93.5% of VDD 6'b011011 - 93.0% of VDD 6'b011100 - 92.5% of VDD 6'b011101 - 92.0% of VDD 6'b011110 - 91.5% of VDD 6'b011111 - 91.0% of VDD 6'b100000 - 90.5% of VDD 6'b100001 - 90.0% of VDD 6'b100010 - 89.0% of VDD 6'b100011 - 88.0% of VDD 6'b100100 - 87.0% of VDD 6'b100101 - 86.0% of VDD 6'b100110 - 85.0% of VDD 6'b100111 - 84.0% of VDD 6'b101000 - 83.0% of VDD 6'b101001 - 82.0% of VDD 6'b101010 - 81.0% of VDD 6'b101011 - 80.0% of VDD 6'b101100 - 79.0% of VDD 6'b101101 - 78.0% of VDD 6'b101110 - 77.0% of VDD 6'b101111 - 76.0% of VDD 6'b110000 - 75.0% of VDD 6'b110001 - 74.0% of VDD 6'b110010 - 73.0% of VDD 6'b110011 - 72.0% of VDD 6'b110100 - 71.0% of VDD 6'b110101 - 70.0% of VDD 6'b110110 - 69.0% of VDD 6'b110111 - 68.0% of VDD 6'b111000 - 67.0% of VDD 6'b111001 - 66.0% of VDD 6'b111010 - 65.0% of VDD 6'b111011 - 64.0% of VDD 6'b111100 - 63.0% of VDD 6'b111101 - 62.0% of VDD 6'b111110 - 61.0% of VDD 6'b111111 - 60.0% of VDD
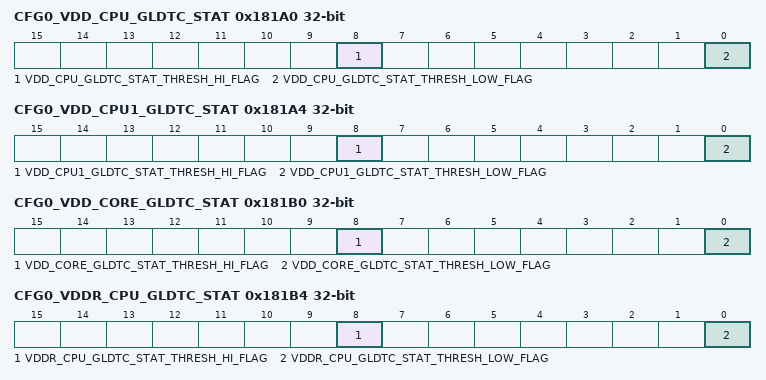
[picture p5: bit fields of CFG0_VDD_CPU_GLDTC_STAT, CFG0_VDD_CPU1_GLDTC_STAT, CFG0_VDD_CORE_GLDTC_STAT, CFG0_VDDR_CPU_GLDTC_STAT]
0x181A0 CFG0_VDD_CPU_GLDTC_STAT ro
  [8] VDD_CPU_GLDTC_STAT_THRESH_HI_FLAG — High voltage flag. This flag is cleared by clearing the VDD_CPU_GLDTC_CTRL_rstb bit. 0 - No high voltage detected 1 - Voltage above the high voltage threshold was detected.
  [0] VDD_CPU_GLDTC_STAT_THRESH_LOW_FLAG — Low voltage flag. This flag is cleared by clearing the VDD_CPU_GLDTC_CTRL_rstb bit. 0 - No low voltage detected 1 - Voltage below the low voltage threshold was detected.
0x181A4 CFG0_VDD_CPU1_GLDTC_STAT ro
  [8] VDD_CPU1_GLDTC_STAT_THRESH_HI_FLAG — High voltage flag. This flag is cleared by clearing the VDD_CPU1_GLDTC_CTRL_rstb bit. 0 - No high voltage detected 1 - Voltage above the high voltage threshold was detected.
  [0] VDD_CPU1_GLDTC_STAT_THRESH_LOW_FLAG — Low voltage flag. This flag is cleared by clearing the VDD_CPU1_GLDTC_CTRL_rstb bit. 0 - No low voltage detected 1 - Voltage below the low voltage threshold was detected.
0x181B0 CFG0_VDD_CORE_GLDTC_STAT ro
  [8] VDD_CORE_GLDTC_STAT_THRESH_HI_FLAG — High voltage flag. This flag is cleared by clearing the VDD_CORE_GLDTC_CTRL_rstb bit. 0 - No high voltage detected 1 - Voltage above the high voltage threshold was detected.
  [0] VDD_CORE_GLDTC_STAT_THRESH_LOW_FLAG — Low voltage flag. This flag is cleared by clearing the VDD_CORE_GLDTC_CTRL_rstb bit. 0 - No low voltage detected 1 - Voltage below the low voltage threshold was detected.
0x181B4 CFG0_VDDR_CPU_GLDTC_STAT ro
  [8] VDDR_CPU_GLDTC_STAT_THRESH_HI_FLAG — High voltage flag. This flag is cleared by clearing the VDDR_CPU_GLDTC_CTRL_rstb bit. 0 - No high voltage detected 1 - Voltage above the high voltage threshold was detected.
  [0] VDDR_CPU_GLDTC_STAT_THRESH_LOW_FLAG — Low voltage flag. This flag is cleared by clearing the VDDR_CPU_GLDTC_CTRL_rstb bit. 0 - No low voltage detected 1 - Voltage below the low voltage threshold was detected.
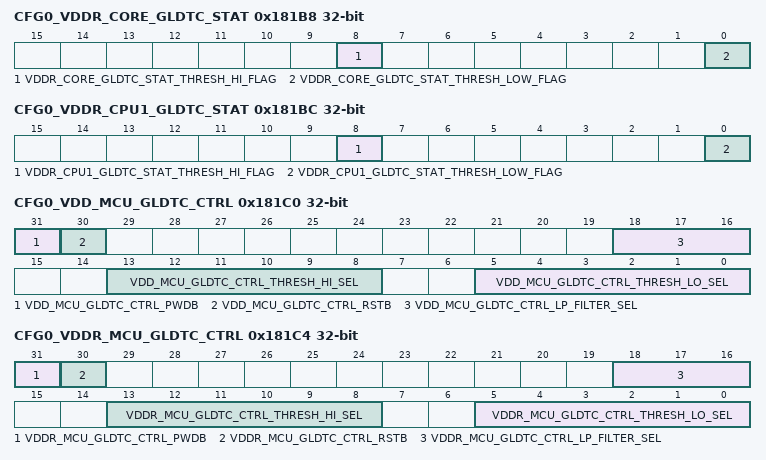
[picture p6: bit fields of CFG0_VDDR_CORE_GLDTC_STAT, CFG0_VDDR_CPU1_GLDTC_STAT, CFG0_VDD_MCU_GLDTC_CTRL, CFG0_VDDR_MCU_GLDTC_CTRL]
0x181B8 CFG0_VDDR_CORE_GLDTC_STAT ro
  [8] VDDR_CORE_GLDTC_STAT_THRESH_HI_FLAG — High voltage flag. This flag is cleared by clearing the VDDR_CORE_GLDTC_CTRL_rstb bit. 0 - No high voltage detected 1 - Voltage above the high voltage threshold was detected.
  [0] VDDR_CORE_GLDTC_STAT_THRESH_LOW_FLAG — Low voltage flag. This flag is cleared by clearing the VDDR_CORE_GLDTC_CTRL_rstb bit. 0 - No low voltage detected 1 - Voltage below the low voltage threshold was detected.
0x181BC CFG0_VDDR_CPU1_GLDTC_STAT ro
  [8] VDDR_CPU1_GLDTC_STAT_THRESH_HI_FLAG — High voltage flag. This flag is cleared by clearing the VDDR_CPU1_GLDTC_CTRL_rstb bit. 0 - No high voltage detected 1 - Voltage above the high voltage threshold was detected.
  [0] VDDR_CPU1_GLDTC_STAT_THRESH_LOW_FLAG — Low voltage flag. This flag is cleared by clearing the VDDR_CPU1_GLDTC_CTRL_rstb bit. 0 - No low voltage detected 1 - Voltage below the low voltage threshold was detected.
0x181C0 CFG0_VDD_MCU_GLDTC_CTRL
  [31] VDD_MCU_GLDTC_CTRL_PWDB — Power down - active low. 0 - Disable all functions 1 - Enable glitch detectors
  [30] VDD_MCU_GLDTC_CTRL_RSTB — Reset - active low. To ensure proper operation, rstb must be not be de-asserted for at least 100 ns after power-up (pwdb de-asserted). Additionally, rstb must be toggled low at least 200 ns after any change in threshold or low-pass filter settings to prevent abnormal trigger events. 0 - Reset glitch detector flags 1 - Glitch detection flags are enabled
  [18:16] VDD_MCU_GLDTC_CTRL_LP_FILTER_SEL — Selects the glitch detect low-pass filter bandwidth Field values (others are reserved): 3'b000 - 150 kHz 3'b001 - 125 kHz 3'b010 - 100 kHz 3'b011 - 80 kHz 3'b100 - 60 kHz 3'b101 - 45 kHz 3'b110 - 30 kHz 3'b111 - 15 kHz
  [13:8] VDD_MCU_GLDTC_CTRL_THRESH_HI_SEL — Selects the high voltage glitch threshold as a percentage of the monitored voltage Field values (others are reserved): 6'b000000 - 93.5% of VDD 6'b000001 - 94.0% of VDD 6'b000010 - 94.5% of VDD 6'b000011 - 95.0% of VDD 6'b000100 - 95.5% of VDD 6'b000101 - 96.0% of VDD 6'b000110 - 96.5% of VDD 6'b000111 - 97.0% of VDD 6'b001000 - 97.5% of VDD 6'b001001 - 98.0% of VDD 6'b001010 - 98.5% of VDD 6'b001011 - 99.0% of VDD 6'b001100 - 99.5% of VDD 6'b001101 - 100.0% of VDD 6'b001110 - 100.5% of VDD 6'b001111 - 101.0% of VDD 6'b010000 - 101.5% of VDD 6'b010001 - 102.0% of VDD 6'b010010 - 102.5% of VDD 6'b010011 - 103.0% of VDD 6'b010100 - 103.5% of VDD 6'b010101 - 104.0% of VDD 6'b010110 - 104.5% of VDD 6'b010111 - 105.0% of VDD 6'b011000 - 105.5% of VDD 6'b011001 - 106.0% of VDD 6'b011010 - 106.5% of VDD 6'b011011 - 107.0% of VDD 6'b011100 - 107.5% of VDD 6'b011101 - 108.0% of VDD 6'b011110 - 108.5% of VDD 6'b011111 - 109.0% of VDD 6'b100000 - 109.5% of VDD 6'b100001 - 110.0% of VDD 6'b100010 - 111.0% of VDD 6'b100011 - 112.0% of VDD 6'b100100 - 113.0% of VDD 6'b100101 - 114.0% of VDD 6'b100110 - 115.0% of VDD 6'b100111 - 116.0% of VDD 6'b101000 - 117.0% of VDD 6'b101001 - 118.0% of VDD 6'b101010 - 119.0% of VDD 6'b101011 - 120.0% of VDD 6'b101100 - 121.0% of VDD 6'b101101 - 122.0% of VDD 6'b101110 - 123.0% of VDD 6'b101111 - 124.0% of VDD 6'b110000 - 125.0% of VDD 6'b110001 - 126.0% of VDD 6'b110010 - 127.0% of VDD 6'b110011 - 128.0% of VDD 6'b110100 - 129.0% of VDD 6'b110101 - 130.0% of VDD 6'b110110 - 131.0% of VDD 6'b110111 - 132.0% of VDD 6'b111000 - 133.0% of VDD 6'b111001 - 134.0% of VDD 6'b111010 - 135.0% of VDD 6'b111011 - 136.0% of VDD 6'b111100 - 137.0% of VDD 6'b111101 - 138.0% of VDD 6'b111110 - 139.0% of VDD 6'b111111 - 140.0% of VDD
  [5:0] VDD_MCU_GLDTC_CTRL_THRESH_LO_SEL — Selects the low voltage glitch threshold as a percentage of the monitored voltage Field values (others are reserved): 6'b000000 - 106.5% of VDD 6'b000001 - 106.0% of VDD 6'b000010 - 105.5% of VDD 6'b000011 - 105.0% of VDD 6'b000100 - 104.5% of VDD 6'b000101 - 104.0% of VDD 6'b000110 - 103.5% of VDD 6'b000111 - 103.0% of VDD 6'b001000 - 102.5% of VDD 6'b001001 - 102.0% of VDD 6'b001010 - 101.5% of VDD 6'b001011 - 101.0% of VDD 6'b001100 - 100.5% of VDD 6'b001101 - 100.0% of VDD 6'b001110 - 99.5% of VDD 6'b001111 - 99.0% of VDD 6'b010000 - 98.5% of VDD 6'b010001 - 98.0% of VDD 6'b010010 - 97.5% of VDD 6'b010011 - 97.0% of VDD 6'b010100 - 96.5% of VDD 6'b010101 - 96.0% of VDD 6'b010110 - 95.5% of VDD 6'b010111 - 95.0% of VDD 6'b011000 - 94.5% of VDD 6'b011001 - 94.0% of VDD 6'b011010 - 93.5% of VDD 6'b011011 - 93.0% of VDD 6'b011100 - 92.5% of VDD 6'b011101 - 92.0% of VDD 6'b011110 - 91.5% of VDD 6'b011111 - 91.0% of VDD 6'b100000 - 90.5% of VDD 6'b100001 - 90.0% of VDD 6'b100010 - 89.0% of VDD 6'b100011 - 88.0% of VDD 6'b100100 - 87.0% of VDD 6'b100101 - 86.0% of VDD 6'b100110 - 85.0% of VDD 6'b100111 - 84.0% of VDD 6'b101000 - 83.0% of VDD 6'b101001 - 82.0% of VDD 6'b101010 - 81.0% of VDD 6'b101011 - 80.0% of VDD 6'b101100 - 79.0% of VDD 6'b101101 - 78.0% of VDD 6'b101110 - 77.0% of VDD 6'b101111 - 76.0% of VDD 6'b110000 - 75.0% of VDD 6'b110001 - 74.0% of VDD 6'b110010 - 73.0% of VDD 6'b110011 - 72.0% of VDD 6'b110100 - 71.0% of VDD 6'b110101 - 70.0% of VDD 6'b110110 - 69.0% of VDD 6'b110111 - 68.0% of VDD 6'b111000 - 67.0% of VDD 6'b111001 - 66.0% of VDD 6'b111010 - 65.0% of VDD 6'b111011 - 64.0% of VDD 6'b111100 - 63.0% of VDD 6'b111101 - 62.0% of VDD 6'b111110 - 61.0% of VDD 6'b111111 - 60.0% of VDD
0x181C4 CFG0_VDDR_MCU_GLDTC_CTRL
  [31] VDDR_MCU_GLDTC_CTRL_PWDB — Power down - active low. 0 - Disable all functions 1 - Enable glitch detectors
  [30] VDDR_MCU_GLDTC_CTRL_RSTB — Reset - active low. To ensure proper operation, rstb must be not be de-asserted for at least 100 ns after power-up (pwdb de-asserted). Additionally, rstb must be toggled low at least 200 ns after any change in threshold or low-pass filter settings to prevent abnormal trigger events. 0 - Reset glitch detector flags 1 - Glitch detection flags are enabled
  [18:16] VDDR_MCU_GLDTC_CTRL_LP_FILTER_SEL — Selects the glitch detect low-pass filter bandwidth Field values (others are reserved): 3'b000 - 150 kHz 3'b001 - 125 kHz 3'b010 - 100 kHz 3'b011 - 80 kHz 3'b100 - 60 kHz 3'b101 - 45 kHz 3'b110 - 30 kHz 3'b111 - 15 kHz
  [13:8] VDDR_MCU_GLDTC_CTRL_THRESH_HI_SEL — Selects the high voltage glitch threshold as a percentage of the monitored voltage Field values (others are reserved): 6'b000000 - 93.5% of VDD 6'b000001 - 94.0% of VDD 6'b000010 - 94.5% of VDD 6'b000011 - 95.0% of VDD 6'b000100 - 95.5% of VDD 6'b000101 - 96.0% of VDD 6'b000110 - 96.5% of VDD 6'b000111 - 97.0% of VDD 6'b001000 - 97.5% of VDD 6'b001001 - 98.0% of VDD 6'b001010 - 98.5% of VDD 6'b001011 - 99.0% of VDD 6'b001100 - 99.5% of VDD 6'b001101 - 100.0% of VDD 6'b001110 - 100.5% of VDD 6'b001111 - 101.0% of VDD 6'b010000 - 101.5% of VDD 6'b010001 - 102.0% of VDD 6'b010010 - 102.5% of VDD 6'b010011 - 103.0% of VDD 6'b010100 - 103.5% of VDD 6'b010101 - 104.0% of VDD 6'b010110 - 104.5% of VDD 6'b010111 - 105.0% of VDD 6'b011000 - 105.5% of VDD 6'b011001 - 106.0% of VDD 6'b011010 - 106.5% of VDD 6'b011011 - 107.0% of VDD 6'b011100 - 107.5% of VDD 6'b011101 - 108.0% of VDD 6'b011110 - 108.5% of VDD 6'b011111 - 109.0% of VDD 6'b100000 - 109.5% of VDD 6'b100001 - 110.0% of VDD 6'b100010 - 111.0% of VDD 6'b100011 - 112.0% of VDD 6'b100100 - 113.0% of VDD 6'b100101 - 114.0% of VDD 6'b100110 - 115.0% of VDD 6'b100111 - 116.0% of VDD 6'b101000 - 117.0% of VDD 6'b101001 - 118.0% of VDD 6'b101010 - 119.0% of VDD 6'b101011 - 120.0% of VDD 6'b101100 - 121.0% of VDD 6'b101101 - 122.0% of VDD 6'b101110 - 123.0% of VDD 6'b101111 - 124.0% of VDD 6'b110000 - 125.0% of VDD 6'b110001 - 126.0% of VDD 6'b110010 - 127.0% of VDD 6'b110011 - 128.0% of VDD 6'b110100 - 129.0% of VDD 6'b110101 - 130.0% of VDD 6'b110110 - 131.0% of VDD 6'b110111 - 132.0% of VDD 6'b111000 - 133.0% of VDD 6'b111001 - 134.0% of VDD 6'b111010 - 135.0% of VDD 6'b111011 - 136.0% of VDD 6'b111100 - 137.0% of VDD 6'b111101 - 138.0% of VDD 6'b111110 - 139.0% of VDD 6'b111111 - 140.0% of VDD
  [5:0] VDDR_MCU_GLDTC_CTRL_THRESH_LO_SEL — Selects the low voltage glitch threshold as a percentage of the monitored voltage Field values (others are reserved): 6'b000000 - 106.5% of VDD 6'b000001 - 106.0% of VDD 6'b000010 - 105.5% of VDD 6'b000011 - 105.0% of VDD 6'b000100 - 104.5% of VDD 6'b000101 - 104.0% of VDD 6'b000110 - 103.5% of VDD 6'b000111 - 103.0% of VDD 6'b001000 - 102.5% of VDD 6'b001001 - 102.0% of VDD 6'b001010 - 101.5% of VDD 6'b001011 - 101.0% of VDD 6'b001100 - 100.5% of VDD 6'b001101 - 100.0% of VDD 6'b001110 - 99.5% of VDD 6'b001111 - 99.0% of VDD 6'b010000 - 98.5% of VDD 6'b010001 - 98.0% of VDD 6'b010010 - 97.5% of VDD 6'b010011 - 97.0% of VDD 6'b010100 - 96.5% of VDD 6'b010101 - 96.0% of VDD 6'b010110 - 95.5% of VDD 6'b010111 - 95.0% of VDD 6'b011000 - 94.5% of VDD 6'b011001 - 94.0% of VDD 6'b011010 - 93.5% of VDD 6'b011011 - 93.0% of VDD 6'b011100 - 92.5% of VDD 6'b011101 - 92.0% of VDD 6'b011110 - 91.5% of VDD 6'b011111 - 91.0% of VDD 6'b100000 - 90.5% of VDD 6'b100001 - 90.0% of VDD 6'b100010 - 89.0% of VDD 6'b100011 - 88.0% of VDD 6'b100100 - 87.0% of VDD 6'b100101 - 86.0% of VDD 6'b100110 - 85.0% of VDD 6'b100111 - 84.0% of VDD 6'b101000 - 83.0% of VDD 6'b101001 - 82.0% of VDD 6'b101010 - 81.0% of VDD 6'b101011 - 80.0% of VDD 6'b101100 - 79.0% of VDD 6'b101101 - 78.0% of VDD 6'b101110 - 77.0% of VDD 6'b101111 - 76.0% of VDD 6'b110000 - 75.0% of VDD 6'b110001 - 74.0% of VDD 6'b110010 - 73.0% of VDD 6'b110011 - 72.0% of VDD 6'b110100 - 71.0% of VDD 6'b110101 - 70.0% of VDD 6'b110110 - 69.0% of VDD 6'b110111 - 68.0% of VDD 6'b111000 - 67.0% of VDD 6'b111001 - 66.0% of VDD 6'b111010 - 65.0% of VDD 6'b111011 - 64.0% of VDD 6'b111100 - 63.0% of VDD 6'b111101 - 62.0% of VDD 6'b111110 - 61.0% of VDD 6'b111111 - 60.0% of VDD
